AUTOSAR XML (schema 4-3-0)
package /Dimmer
  application-sw-component-type:
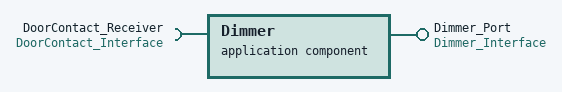
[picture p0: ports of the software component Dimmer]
    application sw component type Dimmer
      require port DoorContact_Receiver: nonqueued-receiver-com-spec=DoorContact_Status, required-interface=DoorContact_Interface
      provide port Dimmer_Port: nonqueued-sender-com-spec=Dimmer_Status, provided-interface=Dimmer_Interface
      behavior Dimmer_InternalBehavior
    swc implementation Dimmer_Implementation: behavior=Dimmer_InternalBehavior
